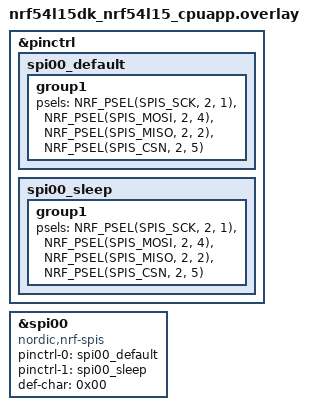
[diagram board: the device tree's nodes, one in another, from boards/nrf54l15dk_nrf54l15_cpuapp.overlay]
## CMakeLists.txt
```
# Copyright (c) 2023 ELMODIS Ltd.

cmake_minimum_required(VERSION 3.20.0)

find_package(Zephyr REQUIRED HINTS $ENV{ZEPHYR_BASE})
project(hello_world)

target_sources(app PRIVATE
    src/main.c
    src/ade9000.c
    src/ade9000Estimates.c
    src/ade9000Interface.c
    src/ble_gatt_service.c
    src/bas_gatt.c
    ${app_sources}
)

zephyr_library_include_directories(${ZEPHYR_BASE}/samples/bluetooth)
```

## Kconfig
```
# Copyright (c) 2023 ELMODIS Ltd.

mainmenu "Elmodis EnergyTag demo"

config ADC_MAX_NUMBER_OF_CHANNELS
	int "Maximum nubmer of ADC channels"
	range 0 255
	help
	  CONFIG_ADC_MAX_NUMBER_OF_CHANNELS must be defined in your prj.conf file

config ADC_CHANNEL_NAMES_USE
	bool "Use channel names assignment"
	default n
	help
	  Enables channel names feature for ADC stucture

config ESTIMATES_QUEUE_SIZE
	int "Size of estimates queue"
	default 1

source "Kconfig.zephyr"
```

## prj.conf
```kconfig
# nothing here
CONFIG_SPI=y
CONFIG_SPI_ASYNC=y
CONFIG_SPI_SLAVE=y
CONFIG_SPI_LOG_LEVEL_INF=y
CONFIG_DEBUG_OPTIMIZATIONS=y
```

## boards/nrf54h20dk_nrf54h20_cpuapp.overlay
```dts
&pinctrl {
	grtc_default_alt: grtc_default_alt {
		group1 {
			psels = <NRF_PSEL(GRTC_CLKOUT_32K, 0, 1)>,
				<NRF_PSEL(GRTC_CLKOUT_FAST, 1, 8)>;
		};
	};
};

&grtc {
	compatible = "nordic,nrf-grtc";
	pinctrl-0 = <&grtc_default_alt>;
	pinctrl-names = "default";
};
```

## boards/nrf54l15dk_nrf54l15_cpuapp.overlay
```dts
&pinctrl {
    spi00_default: spi00_default {
        group1 {
            psels = <NRF_PSEL(SPIS_SCK, 2, 1)>,  /* SCK Input */
                    <NRF_PSEL(SPIS_MOSI, 2, 4)>, /* MOSI Input */
                    <NRF_PSEL(SPIS_MISO, 2, 2)>, /* MISO Output */
                    <NRF_PSEL(SPIS_CSN, 2, 5)>;  /* CS Input - Must be here! */
        };
    };
    spi00_sleep: spi00_sleep {
        group1 {
            psels = <NRF_PSEL(SPIS_SCK, 2, 1)>,  /* SCK Input */
                    <NRF_PSEL(SPIS_MOSI, 2, 4)>, /* MOSI Input */
                    <NRF_PSEL(SPIS_MISO, 2, 2)>, /* MISO Output */
                    <NRF_PSEL(SPIS_CSN, 2, 5)>;  /* CS Input - Must be here! */
        };
    };
};

&spi00 {
    status = "okay";
    compatible = "nordic,nrf-spis";
    pinctrl-0 = <&spi00_default>;
    pinctrl-1 = <&spi00_sleep>;
    pinctrl-names = "default","sleep";
    def-char = <0x00>;
    /delete-property/ rx-delay-supported;
    /delete-property/ rx-delay;
};
```

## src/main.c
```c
#include <zephyr/device.h>
#include <zephyr/devicetree.h>
#include <zephyr/kernel.h>
#include <zephyr/types.h>
#include <zephyr/drivers/spi.h>

#define SPI_NODE DT_NODELABEL(spi00)
static const struct device *spi_dev = DEVICE_DT_GET(SPI_NODE);

struct spi_config spis_cfg = {
          .frequency = 0, /* Frequency is controlled entirely by the Master */
        .operation = SPI_WORD_SET(8) | SPI_OP_MODE_SLAVE,
};



int main(void)
{
	int err;
	int ret;
	int ret_val;
	uint8_t rx_buffer[32] = {
	                  0xab,0xcd,0xef,0xee,0xaa,0xff,0x12,0x89,
	                  0xab,0xcd,0xef,0xee,0xaa,0xff,0x12,0x89,
	                  0xab,0xcd,0xef,0xee,0xaa,0xff,0x12,0x89,
	                  0xab,0xcd,0xef,0xee,0xaa,0xff,0x12,0x89
	                        };
	uint8_t tx_buffer[32] = {
	                  0xab,0xcd,0xef,0xee,0xaa,0xff,0x12,0x89,
	                  0xab,0xcd,0xef,0xee,0xaa,0xff,0x12,0x89,
	                  0xab,0xcd,0xef,0xee,0xaa,0xff,0x12,0x89,
	                  0xab,0xcd,0xef,0xee,0xaa,0xff,0x12,0x89
	                        };


    if (!device_is_ready(spi_dev)) {
		printk("UART device not found!");
		return 0;
	}

	while (true) {
			printk("waiting for request\r\n");
		
    struct spi_buf tx_buf = { .buf = tx_buffer, .len = sizeof(tx_buffer) };
    struct spi_buf_set tx_bufs = { .buffers = &tx_buf, .count = 1 };

    struct spi_buf rx_buf = { .buf = rx_buffer, .len = sizeof(rx_buffer) };
    struct spi_buf_set rx_bufs = { .buffers = &rx_buf, .count = 1 };
  		ret = spi_transceive(spi_dev, &spis_cfg, &tx_bufs, &rx_bufs);
        printk("received %d bytes:", ret);
        for (int i = 0; i < ret && i < sizeof(rx_buffer); i++) {
                printk(" %02x", rx_buffer[i]);
        }
        printk("\n");

  		printk("spi work done\n");
				
	}

	/* return to idle thread */
	return 0;
}
```

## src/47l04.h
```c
/*
 * Copyright (c) 2023 ELMODIS Ltd.
 */

#define L04_ADDR           0x20
#define L04_SCL_PIN        27
#define L04_SDA_PIN        26

// 47L04-I/ST register addresses
#define L04_REG_INPUT      0x00
#define L04_REG_OUTPUT     0x01
#define L04_REG_CONFIG     0x03
```

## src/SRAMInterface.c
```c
/*
 * Copyright (c) 2023 ELMODIS Ltd.
 */

#include "SRAMInterface.h"
#include <zephyr/kernel.h>

// TODO: Get from config
//#define LOG_SRAMINTERFACE 1
#define SRAM_TX_BUFFER_SIZE 16
#define SRAM_RX_BUFFER_SIZE 16

#if defined(LOG_SRAMINTERFACE) && (LOG_SRAMINTERFACE == 1)
#include <zephyr/sys/printk.h>
#endif

//TODO: Get it from DeviceTree
#define SRAM_CS_PIN   29//0x1F // 31
#define SRAM_MOSI_PIN 17 // 32
//TODO: This pin is temporary and should be 15 (some DK/DTS problems?)
#define SRAM_MISO_PIN (32 + 11) // 15
#define SRAM_SCK_PIN  13 // default 22

static volatile uint8_t m_rx_buffer[16];
static volatile uint8_t m_tx_buffer[16];

static volatile bool spi_flag = true;

static void WaitForTransferEnd(bool resetFlag)
{
    while(!spi_flag);
    if (resetFlag) {
        spi_flag = false;
    }
}

static void spim_handler(const nrfx_spim_evt_t *p_event, void *p_context)
{
	if (p_event->type == NRFX_SPIM_EVENT_DONE) {
#if defined(LOG_SRAMINTERFACE) && (LOG_SRAMINTERFACE == 1)
        printk(" (IRQ)\n");
#endif
        spi_flag = true;
        memset((void*)m_tx_buffer , 0 , sizeof(m_tx_buffer));
	}
}

#warning change instance
static const nrfx_spim_t spi_inst = NRFX_SPIM_INSTANCE(2);

static bool SPIInit(void)
{
    nrfx_spim_config_t spi_config = NRFX_SPIM_DEFAULT_CONFIG(SRAM_SCK_PIN,
                                                             SRAM_MOSI_PIN,
                                                             SRAM_MISO_PIN,
                                                             SRAM_CS_PIN);

    return nrfx_spim_init(&spi_inst, &spi_config, spim_handler, NULL) == NRFX_SUCCESS ?
           true : false;
}

bool SRAMInit(void)
{
    /*if (!SRAMInterfaceInit()) {
        return false;
    }*/
    if (!SPIInit()) {
        return false;
    }
    return true;
}

bool SRAMWrite(uint32_t addr, uint8_t const * const data, size_t length)
{
    WaitForTransferEnd(true);
    addr &= 0x00FFFFFF;
    m_tx_buffer[0] = 0x02;
    m_tx_buffer[1] = (uint8_t)(addr >> 16);
    m_tx_buffer[2] = (uint8_t)(addr >> 8);
    m_tx_buffer[3] = (uint8_t)(addr >> 0);
    memcpy((uint8_t*)&m_tx_buffer[4], (uint8_t*)data, length);
    length += 4;
    nrfx_spim_xfer_desc_t spim_xfer_desc = NRFX_SPIM_XFER_TX(m_tx_buffer, 4 + length);
    nrfx_err_t err = nrfx_spim_xfer(&spi_inst, &spim_xfer_desc, 0);
    return err == NRFX_SUCCESS;
}

uint8_t * SRAMRead(uint32_t addr, size_t length)
{
    WaitForTransferEnd(true);
    addr &= 0x00FFFFFF;
    m_tx_buffer[0] = 0x03;
    m_tx_buffer[1] = (uint8_t)(addr >> 16);
    m_tx_buffer[2] = (uint8_t)(addr >> 8);
    m_tx_buffer[3] = (uint8_t)(addr >> 0);

    memset((uint8_t*)m_rx_buffer, 0, sizeof(m_rx_buffer));
    
    nrfx_spim_xfer_desc_t spim_xfer_desc = NRFX_SPIM_XFER_TRX(m_tx_buffer, 4 ,(uint8_t*)m_rx_buffer , length + 4);
    nrfx_err_t err = nrfx_spim_xfer(&spi_inst, &spim_xfer_desc, 0);
    WaitForTransferEnd(false);
    return err == NRFX_SUCCESS ? &m_rx_buffer[4] : NULL;
}

bool SRAMIDRead(uint8_t * id)
{
    WaitForTransferEnd(true);
    uint32_t addr = 0xFFFFFFFF;
    size_t length = 8;
    m_tx_buffer[0] = 0x9F;
    m_tx_buffer[1] = (uint8_t)(addr >> 16);
    m_tx_buffer[2] = (uint8_t)(addr >> 8);
    m_tx_buffer[3] = (uint8_t)(addr >> 0);

    memset((uint8_t*)m_rx_buffer, 0, sizeof(m_rx_buffer));
    
    nrfx_spim_xfer_desc_t spim_xfer_desc = NRFX_SPIM_XFER_TRX(m_tx_buffer, 4 ,(uint8_t*)m_rx_buffer , length + 4);
    nrfx_err_t err = nrfx_spim_xfer(&spi_inst, &spim_xfer_desc, 0);
    WaitForTransferEnd(false);
    id = (uint8_t*)m_rx_buffer;
    return err == NRFX_SUCCESS;
}

void SRAMReset(void)
{
    //0x66, 0x99
    WaitForTransferEnd(true);
    m_tx_buffer[0] = 0x66;
    
    size_t length = 1;
    nrfx_spim_xfer_desc_t spim_xfer_desc = NRFX_SPIM_XFER_TX(m_tx_buffer, length);
    (void)nrfx_spim_xfer(&spi_inst, &spim_xfer_desc, 0);
    WaitForTransferEnd(true);
    k_sleep(K_MSEC(10));
    m_tx_buffer[0] = 0x99;
    (void)nrfx_spim_xfer(&spi_inst, &spim_xfer_desc, 0);
    WaitForTransferEnd(false);
}
```

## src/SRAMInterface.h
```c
/*
 * Copyright (c) 2023 ELMODIS Ltd.
 */

#ifndef SRAMINTERFACE_H
#define SRAMINTERFACE_H

#include <nrfx_spim.h>
#include <stdlib.h>
#include <string.h>

bool SRAMInit(void);

bool SRAMWrite(uint32_t addr, uint8_t const * const data, size_t length);

uint8_t * SRAMRead(uint32_t addr, size_t length);

bool SRAMIDRead(uint8_t * id);

void SRAMReset(void);

#endif // SRAMINTERFACE_H
```

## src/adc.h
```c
#ifndef ADC_H
#define ADC_H

typedef struct {
    bool (*initialize)(void *);
    bool (*configure)(void *);
    bool (*start) (void *);
    bool (*stop) (void *);
    bool (*channel_read) (uint8_t chan, void *);
    bool (*all_channels_read) (void *);
#if IS_ENABLED(CONFIG_ADC_CHANNEL_NAMES_USE)
    const char *channel_name[CONFIG_ADC_MAX_NUMBER_OF_CHANNELS];
#endif
} adc_t;

#define ADC_INITIALIZE_STRUCT(        			 \
            init_func,                			 \
            config_func,              			 \
            start_func,               			 \
            stop_func,                			 \
            channel_read_func,				 \
	    all_channels_read_func)                	 \
        {                             			 \
            .initialize = init_func,  			 \
            .configure = config_func, 			 \
            .start = start_func,      			 \
	    .stop = stop_func,        			 \
	    .channel_read = channel_read_func, 		 \
	    .all_channels_read = all_channels_read_func  \
        }

#if IS_ENABLED(CONFIG_ADC_CHANNEL_NAMES_USE)
#define ADC_CHANNEL_NAME_ASSIGN(adc, channel, name) \
	adc.channel_name[channel] = name

#define ADC_CHANNEL_NAME_GET(adc, channel) \
	adc.channel_name[channel]
#endif

#endif // ADC_H
```

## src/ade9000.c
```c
/*
 * Copyright (c) 2023 ELMODIS Ltd.
 */

#include <zephyr/drivers/gpio.h>
#include <zephyr/kernel.h>
#if 1
#include <zephyr/sys/printk.h>
#endif

#include "ade9000_registers.h"
#include "ade9000Estimates.h"

//#define ADE9000_PM0_NODE   DT_ALIAS(ade9000pm0)
#define ADE9000_PM1_NODE   DT_ALIAS(ade9000pm1)
#define ADE9000_RESET_NODE DT_ALIAS(ade9000reset)
#define ADE9000_DRDY_NODE  DT_ALIAS(ade9000drdy)
#define ADE9000_IRQ0_NODE  DT_ALIAS(ade9000irq0)
#define ADE9000_IRQ1_NODE  DT_ALIAS(ade9000irq1)

// TODO: Move out and rework when error handling will be finished.
#define CHECK_RESULT_BOOL(expression) \
        if (!expression) return false;

//static const struct gpio_dt_spec pm0   = GPIO_DT_SPEC_GET(ADE9000_PM0_NODE, gpios);
static const struct gpio_dt_spec pm1   = GPIO_DT_SPEC_GET(ADE9000_PM1_NODE, gpios);
static const struct gpio_dt_spec reset = GPIO_DT_SPEC_GET(ADE9000_RESET_NODE, gpios);
static const struct gpio_dt_spec drdy  = GPIO_DT_SPEC_GET(ADE9000_DRDY_NODE, gpios);
static const struct gpio_dt_spec irq0  = GPIO_DT_SPEC_GET(ADE9000_IRQ0_NODE, gpios);
static const struct gpio_dt_spec irq1  = GPIO_DT_SPEC_GET(ADE9000_IRQ1_NODE, gpios);

typedef enum {
    PM_Reduced = 0,
    PM_Normal  = 1,
    PM_Low     = 2,
    PM_Sleep   = 3
} ade9000_power_mode_t;

#define TEST_REG 0x4FE
#define EXPECTED_TEST_RESULT 0x00FE

#define TEST_MES  0xCFE

static bool GPIOConfig(void)
{
    int ret;
    // TODO: Looks bad. Array of pins to be initialized/configured
    if (!device_is_ready(reset.port)) {
		return false;
	}
	ret = gpio_pin_configure_dt(&reset, GPIO_OUTPUT_INACTIVE);
	if (ret < 0) {
		return false;
	}
    gpio_pin_set_dt(&reset, 1);
    //TODO: Check those timings.
    k_msleep(100);

  /*if (!device_is_ready(pm0.port)) {
		return false;
	}
	ret = gpio_pin_configure_dt(&pm0, GPIO_OUTPUT_ACTIVE);
	if (ret < 0) {
		return false;
	}*/

    if (!device_is_ready(pm1.port)) {
		return false;
	}
	ret = gpio_pin_configure_dt(&pm1, GPIO_OUTPUT_ACTIVE);
	if (ret < 0) {
		return false;
	}

    if (!device_is_ready(drdy.port)) {
		return false;
	}
	ret = gpio_pin_configure_dt(&drdy, GPIO_INPUT);
	if (ret < 0) {
		return false;
	}

    if (!device_is_ready(irq0.port)) {
		return false;
	}
	ret = gpio_pin_configure_dt(&irq0, GPIO_INPUT);
	if (ret < 0) {
		return false;
	}

    if (!device_is_ready(irq1.port)) {
		return false;
	}
	ret = gpio_pin_configure_dt(&irq1, GPIO_INPUT);
	if (ret < 0) {
		return false;
	}

    gpio_pin_set_dt(&irq0, 1);
    gpio_pin_set_dt(&irq1, 1);

    return true;
}

static bool PowerModeSet(ade9000_power_mode_t mode)
{
    switch(mode) {
        case PM_Normal:
            //gpio_pin_set_dt(&pm0, 0);
            gpio_pin_set_dt(&pm1, 0);
            break;
        default:
            // Other modes not supported at the moment.
            return false;
  }

  return true;
}
static void StoreCoeffs(SEleFlashDataCal *fd)
{
	int32_t default_coeff = 0;
	if (fd != NULL) {
	// TODO: Currently not supported
	while(1);
	}
	//default_coeff = 14528733;
	default_coeff = 383;
	ADE9000InterfaceRegWriteAndCheck(R_APHCAL0, default_coeff, 4);
	ADE9000InterfaceRegWriteAndCheck(R_BPHCAL0, default_coeff, 4);
	ADE9000InterfaceRegWriteAndCheck(R_CPHCAL0, default_coeff, 4);

	default_coeff = 0;
	ADE9000InterfaceRegWriteAndCheck(R_AIGAIN, -95119123, 4);
	ADE9000InterfaceRegWriteAndCheck(R_BIGAIN, -94938644, 4);
	ADE9000InterfaceRegWriteAndCheck(R_CIGAIN, -95003782, 4);

	default_coeff = 0;
	ADE9000InterfaceRegWriteAndCheck(R_AVGAIN, -115926529, 4);
	ADE9000InterfaceRegWriteAndCheck(R_BVGAIN, -115971651, 4);
	ADE9000InterfaceRegWriteAndCheck(R_CVGAIN, -115894056, 4);

	default_coeff = 0;
	ADE9000InterfaceRegWriteAndCheck(R_AIRMSOS, default_coeff, 4);
	ADE9000InterfaceRegWriteAndCheck(R_BIRMSOS, default_coeff, 4);
	ADE9000InterfaceRegWriteAndCheck(R_CIRMSOS, default_coeff, 4);

	default_coeff = 0;
	ADE9000InterfaceRegWriteAndCheck(R_AVRMSOS, default_coeff, 4);
	ADE9000InterfaceRegWriteAndCheck(R_BVRMSOS, default_coeff, 4);
	ADE9000InterfaceRegWriteAndCheck(R_CVRMSOS, default_coeff, 4);

	default_coeff = 0;
	ADE9000InterfaceRegWriteAndCheck(R_AWATTOS, default_coeff, 4);
	ADE9000InterfaceRegWriteAndCheck(R_BWATTOS, default_coeff, 4);
	ADE9000InterfaceRegWriteAndCheck(R_CWATTOS, default_coeff, 4);

	default_coeff = 0;
	ADE9000InterfaceRegWriteAndCheck(R_AVAROS, default_coeff, 4);
	ADE9000InterfaceRegWriteAndCheck(R_BVAROS, default_coeff, 4);
	ADE9000InterfaceRegWriteAndCheck(R_CVAROS, default_coeff, 4);

	default_coeff = 0;
	ADE9000InterfaceRegWriteAndCheck(R_APGAIN, 45687846, 4);
	ADE9000InterfaceRegWriteAndCheck(R_BPGAIN, 45903740, 4);
	ADE9000InterfaceRegWriteAndCheck(R_CPGAIN, 45847370, 4);
}

void EnergyAccConfigure(void)
{
    //aktywujemy i konfigurujemy akumulator energii
    //reg.S_EP_CFG.RD_RST_EN = 1;
    ade9000_reg32_t reg;
    uint32_t no_load_thr = 2;
    reg.v = no_load_thr * 64;
    ADE9000InterfaceRegWrite(R_ACT_NL_LVL, reg.v, sizeof(reg.S_ACT_NL_LVL));
    ADE9000InterfaceRegWrite(R_REACT_NL_LVL, reg.v, sizeof(reg.S_REACT_NL_LVL));
    ADE9000InterfaceRegWrite(R_APP_NL_LVL, reg.v, sizeof(reg.S_APP_NL_LVL));

    reg.v = 0;
    reg.S_EP_CFG.EGY_PWR_EN = 1;//Set this bit to enable the energy and power accumulator
    reg.S_EP_CFG.RD_RST_EN = 1;//Every read causes reset energy accumulator
    ADE9000InterfaceRegWrite(R_EP_CFG, reg.v, sizeof(reg.S_EP_CFG));

    reg.v = 8000;//Energy accumulation update time configuration.
    ADE9000InterfaceRegWrite(R_EGY_TIME, reg.v, sizeof(reg.S_EGY_TIME));

    reg.v = 0;
    reg.S_ACCMODE.WATTACC = 2;//Positive Accumuation Mode.
    reg.S_ACCMODE.VARACC = 2;//Positive Accumuation Mode.
    ADE9000InterfaceRegWrite(R_ACCMODE, reg.v, sizeof(reg.S_ACCMODE));
}

bool ADE9000Init(void * params)
{
	(void)params;
	if (!GPIOConfig()) {
	return false;
	}
	if (!PowerModeSet(PM_Normal)) {
	return false;
	}
	if (!ADE9000InterfaceInit()) {
	return false;
	}
	//TODO: Check those timings.
	k_msleep(10);
	gpio_pin_set_dt(&reset, 0);
	//TODO: Check those timings.
	k_msleep(100);

	return true;
}

bool ADE9000MeasParamsSet(void * params)
{
    (void)params;
    uint8_t i_gain = 1;
    uint8_t v_gain = 1;
    uint16_t u_g = v_gain - 1, i_g = i_gain - 1;
    ade9000_reg32_t reg;

    reg.v = 0;
    reg.S_PGA_GAIN.VA_GAIN = u_g;
    reg.S_PGA_GAIN.VB_GAIN = u_g;
    reg.S_PGA_GAIN.VC_GAIN = u_g;
    reg.S_PGA_GAIN.IA_GAIN = i_g;
    reg.S_PGA_GAIN.IB_GAIN = i_g;
    reg.S_PGA_GAIN.IC_GAIN = i_g;
    reg.S_PGA_GAIN.IN_GAIN = i_g;


    StoreCoeffs(NULL);
    EnergyAccConfigure();
    ADE9000InterfaceRegWriteAndCheck(R_PGA_GAIN, reg.v, 2);

    reg.v = 0;
    reg.S_ACCMODE.SELFSREQ = 1;
    ADE9000InterfaceRegWriteAndCheck(R_ACCMODE, reg.v,2);

    ADE9000InterfaceRegWriteAndCheck(R_DICOEFF, 0xFFFFE000, 4);
    ADE9000InterfaceRegRead(R_CONFIG0, &reg.v, sizeof(reg.S_CONFIG0));
    reg.S_CONFIG0.INTEN = 1;
    CHECK_RESULT_BOOL(ADE9000InterfaceRegWriteAndCheck(R_CONFIG0, reg.v, sizeof(reg.S_CONFIG0)));

    return true;
}


bool ADE9000ConversionStart(void * params)
{
  (void)params;
  ade9000_reg32_t reg, r_reg;
  //ADCData.MeasInProgress = 1;
  reg.v = 0;
  CHECK_RESULT_BOOL(ADE9000InterfaceRegWriteAndCheck(R_WFB_PG_IRQEN, 0x8080, 2));
  //konfiguracja przebiegow:
  CHECK_RESULT_BOOL(ADE9000InterfaceRegWriteAndCheck(R_WFB_CFG, reg.v,sizeof(reg.S_WFB_CFG)));
  reg.S_WFB_CFG.WF_MODE = 3;
  reg.S_WFB_CFG.WF_CAP_SEL = 1;
  reg.S_WFB_CFG.WF_CAP_EN = 1;
  reg.S_WFB_CFG.WF_SRC = 3;
  CHECK_RESULT_BOOL(ADE9000InterfaceRegWriteAndCheck(R_WFB_CFG, reg.v, sizeof(reg.S_WFB_CFG)));
  ADE9000InterfaceRegRead(R_WFB_CFG, &r_reg.v,sizeof(r_reg.S_WFB_CFG));
  if (r_reg.v != reg.v) return false;

  ADE9000InterfaceRegRead(R_CONFIG1, &reg.v, sizeof(reg.S_CONFIG1));
  reg.S_CONFIG1.BURST_EN = 1;
  reg.S_CONFIG1.CF4_CFG = 0x2;
  CHECK_RESULT_BOOL(ADE9000InterfaceRegWriteAndCheck(R_CONFIG1, reg.v, sizeof(reg.S_CONFIG1)));

  reg.v = 0;
  reg.S_EVENT_MASK.DREADY = 1;
  CHECK_RESULT_BOOL(ADE9000InterfaceRegWriteAndCheck(R_EVENT_MASK, reg.v, sizeof(reg.S_EVENT_MASK)));

  ADE9000InterfaceRegRead(R_RUN, &reg.v, sizeof(reg.S_RUN));

  if (!reg.S_RUN.Start) {
    reg.S_RUN.Start = 1;
    CHECK_RESULT_BOOL(ADE9000InterfaceRegWriteAndCheck(R_RUN,reg.v, sizeof(reg.S_RUN)));
  }

  return true;
}

void ADE9000StreamRead(void)
{
    //ADE9000InterfaceRegRead(R_AV_PCF_1 , (uint8_t*)m_rx_buffer, 28);
    k_sleep(K_SECONDS(1));
}
```

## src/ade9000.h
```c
/*
 * Copyright (c) 2023 ELMODIS Ltd.
 */

#ifndef ADE9000_H
#define ADE9000_H

#include <stdbool.h>

bool ADE9000Init(void * params);

bool ADE9000MeasParamsSet(void * params);

bool ADE9000ConversionStart(void * params);

void ADE9000StreamRead(void);

#endif // ADE9000_H
```

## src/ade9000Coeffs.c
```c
/*
 * Copyright (c) 2023 ELMODIS Ltd.
 */
```

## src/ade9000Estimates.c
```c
/*
 * Copyright (c) 2023 ELMODIS Ltd.
 */

#include <zephyr/kernel.h>
#include <math.h>

#include "ade9000Estimates.h"
#include "ade9000_registers.h"


// TODO: Get from config
#define LOG_ADE9000ESTIMATES 0

#if defined(LOG_ADE9000ESTIMATES) && (LOG_ADE9000ESTIMATES== 1)
#include <zephyr/sys/printk.h>
#endif

typedef struct estimates_seq_t{
  enum Eade9000_register Addr;
  int32_t DstOffs;
  uint8_t Size;
} estimates_seq_t;

static const estimates_seq_t EstimatesReadSequenceTable[] = {
    {R_AIRMS, offsetof(ade_est_data_t, IA), 4 },
    {R_AVRMS, offsetof(ade_est_data_t, VA), 4 },
    {R_BIRMS, offsetof(ade_est_data_t, IB), 4 },
    {R_BVRMS, offsetof(ade_est_data_t, VB), 4 },
    {R_CIRMS, offsetof(ade_est_data_t, IC), 4 },
    {R_CVRMS, offsetof(ade_est_data_t, VC), 4 },

    {R_AWATT, offsetof(ade_est_data_t, AWATT), 4 },
    {R_BWATT, offsetof(ade_est_data_t, BWATT), 4 },
    {R_CWATT, offsetof(ade_est_data_t, CWATT), 4 },

    {R_AVAR, offsetof(ade_est_data_t, AVAR), 4 },
    {R_BVAR, offsetof(ade_est_data_t, BVAR), 4 },
    {R_CVAR, offsetof(ade_est_data_t, CVAR), 4 },

    {R_AVA, offsetof(ade_est_data_t, AVA), 4 },
    {R_BVA, offsetof(ade_est_data_t, BVA), 4 },
    {R_CVA, offsetof(ade_est_data_t, CVA), 4 },

    {R_AWATTHR_HI, offsetof(ade_est_data_t, AWATTHR), 4 },
    {R_BWATTHR_HI, offsetof(ade_est_data_t, BWATTHR), 4 },
    {R_CWATTHR_HI, offsetof(ade_est_data_t, CWATTHR), 4 },

    {R_AVARHR_HI, offsetof(ade_est_data_t, AVARHR), 4 },
    {R_BVARHR_HI, offsetof(ade_est_data_t, BVARHR), 4 },
    {R_CVARHR_HI, offsetof(ade_est_data_t, CVARHR), 4 },

    {R_ANGL_VA_IA, offsetof(ade_est_data_t, Angle0), 2 },
    {R_ANGL_VB_IB, offsetof(ade_est_data_t, Angle1), 2 },
    {R_ANGL_VC_IC, offsetof(ade_est_data_t, Angle2), 2 },
};

static void AdditionalEstimatesCalculate(ade_est_data_t * estimates)
{
	static int32_t ea_last[3];
	static int32_t er_last[3];

	// TODO - remove as it is for 50Hz system only.
	estimates->Angle0 = (int32_t)(0.017578125 * (double)estimates->Angle0);
	estimates->Angle1 = (int32_t)(0.017578125 * (double)estimates->Angle1);
	estimates->Angle2 = (int32_t)(0.017578125 * (double)estimates->Angle2);

	estimates->Imean = (estimates->IA + estimates->IB + estimates->IC) / 3;
	estimates->Umean = (estimates->VA + estimates->VB + estimates->VC) / 3;

	ea_last[0] = (estimates->AWATTHR > 0) ? (ea_last[0] + estimates->AWATTHR) : (ea_last[0]);
	ea_last[1] = (estimates->BWATTHR > 0) ? (ea_last[1] + estimates->BWATTHR) : (ea_last[1]);
	ea_last[2] = (estimates->CWATTHR > 0) ? (ea_last[2] + estimates->CWATTHR) : (ea_last[2]);
	estimates->AWATTHR = ea_last[0];
	estimates->BWATTHR = ea_last[1];
	estimates->CWATTHR = ea_last[2];
	estimates->WATTHR = estimates->AWATTHR + estimates->BWATTHR + estimates->CWATTHR;

	er_last[0] = (estimates->AVARHR > 0) ? (er_last[0] + estimates->AVARHR) : (er_last[0]);
	er_last[1] = (estimates->BVARHR > 0) ? (er_last[1] + estimates->BVARHR) : (er_last[1]);
	er_last[2] = (estimates->CVARHR > 0) ? (er_last[2] + estimates->CVARHR) : (er_last[2]);
	estimates->AVARHR = er_last[0];
	estimates->BVARHR = er_last[1];
	estimates->CVARHR = er_last[2];
	estimates->WARTHR = estimates->AVARHR + estimates->BVARHR + estimates->CVARHR;

	estimates->P = estimates->AWATT + estimates->BWATT + estimates->CWATT;
	estimates->Q = estimates->AVAR + estimates->BVAR + estimates->CVAR;
	estimates->S = estimates->AVA + estimates->BVA + estimates->CVA;

	estimates->VAB = (int32_t)(((estimates->VA + estimates->VB) / 2) * sqrt(3));
	estimates->VBC = (int32_t)(((estimates->VB + estimates->VC) / 2) * sqrt(3));
	estimates->VCA = (int32_t)(((estimates->VC + estimates->VA) / 2) * sqrt(3));
}

bool ADE9000EstimatesAllEstimates1sRead(void *p_est)
{
	//__ASSERT(p_est);
	uint32_t * read_data = (uint32_t *)p_est;
	for(uint32_t i = 0; i < ARRAY_SIZE(EstimatesReadSequenceTable); i ++) {
		if (!ADE9000InterfaceRegRead(EstimatesReadSequenceTable[i].Addr,
            				     &read_data[i],
            				     EstimatesReadSequenceTable[i].Size)) {
			return false;
		}
		while(!ADE9000InterfaceTransferDone()) {
			//TODO: use semaphores?
			k_usleep(10);
		}
	}
	AdditionalEstimatesCalculate((ade_est_data_t *)p_est);
	return true;
}

bool ADE9000EstimatesEstimate1sRead(uint8_t idx, void *p_est)
{
    if (idx >= ARRAY_SIZE(EstimatesReadSequenceTable)) {
      return false;
    }

    ADE9000InterfaceRegRead(EstimatesReadSequenceTable[idx].Addr,
            (uint32_t *)p_est,
            EstimatesReadSequenceTable[idx].Size);
#if defined(LOG_ADE9000ESTIMATES) && (LOG_ADE9000ESTIMATES== 1)
    while(!ADE9000InterfaceTransferDone());
    printk("Estimate(%s) = %d\n", EstimStringArray[idx], (uint32_t)*p_est);
#endif
    return true;
}
```

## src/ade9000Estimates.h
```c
/*
 * Copyright (c) 2023 ELMODIS Ltd.
 */

#ifndef ADE9000ESTIMATES_H
#define ADE9000ESTIMATES_H

#include "ade9000Interface.h"

typedef struct {

} ade9000_read_data_t;

typedef struct ade_est_data_t {
   int32_t IA;
   int32_t VA;
   int32_t IB;
   int32_t VB;
   int32_t IC;
   int32_t VC;

   int32_t AWATT;
   int32_t BWATT;
   int32_t CWATT;

   int32_t AVAR;
   int32_t BVAR;
   int32_t CVAR;

   int32_t AVA;
   int32_t BVA;
   int32_t CVA;

   int32_t AWATTHR;
   int32_t BWATTHR;
   int32_t CWATTHR;

   int32_t AVARHR;
   int32_t BVARHR;
   int32_t CVARHR;

   int32_t Angle0;
   int32_t Angle1;
   int32_t Angle2;

   int32_t VAB;
   int32_t VBC;
   int32_t VCA;

   int32_t Imean;
   int32_t Umean;

   int32_t P;
   int32_t Q;
   int32_t S;

   uint32_t WATTHR;
   uint32_t WARTHR;

   int32_t ModuleTemperature;
   uint32_t PMS;
   uint32_t FrameCounter;
   uint64_t Timestamp;
   uint32_t Checksum;
} ade_est_data_t;

bool ADE9000EstimatesAllEstimates1sRead(void *p_est);

bool ADE9000EstimatesEstimate1sRead(uint8_t idx, void *p_est);

bool ADE9000EstimatesEstimate1sStart(void);

#endif // ADE9000ESTIMATES_H
```

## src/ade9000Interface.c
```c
/*
 * Copyright (c) 2023 ELMODIS Ltd.
 */

#include "ade9000Interface.h"

// TODO: Get from config
//#define LOG_ADE9000INTERFACE 1

#if defined(LOG_ADE9000INTERFACE) && (LOG_ADE9000INTERFACE == 1)
#include <zephyr/sys/printk.h>
#endif

//TODO: Get it from DeviceTree
#define ADE9000_CS_PIN   0x1F // 31
#define ADE9000_MOSI_PIN 0X20 // 32
#define ADE9000_MISO_PIN 0x18 // 24
#define ADE9000_SCK_PIN  22 // default 22

static volatile uint8_t m_rx_buffer[6];
static volatile uint8_t m_tx_buffer[4];

static volatile bool spi_flag = true;

static void WaitForTransferEnd(bool resetFlag)
{
    while(!spi_flag);
    if (resetFlag) {
        spi_flag = false;
    }
}

static void spim_handler(const nrfx_spim_evt_t *p_event, void *p_context)
{
	if (p_event->type == NRFX_SPIM_EVENT_DONE) {
#if defined(LOG_ADE9000INTERFACE) && (LOG_ADE9000INTERFACE == 1)
        printk(" (IRQ)\n");
#endif
        spi_flag = true;
        memset((void*)m_tx_buffer , 0 , sizeof(m_tx_buffer));
	}
}

bool ADE9000InterfaceTransferDone(void)
{
    return spi_flag;
}

static const nrfx_spim_t spi_inst = NRFX_SPIM_INSTANCE(1);

static bool SPIInit(void)
{
    nrfx_spim_config_t spi_config = NRFX_SPIM_DEFAULT_CONFIG(ADE9000_SCK_PIN,
                                                             ADE9000_MOSI_PIN,
                                                             ADE9000_MISO_PIN,
                                                             ADE9000_CS_PIN);

    return nrfx_spim_init(&spi_inst, &spi_config, spim_handler, NULL) == NRFX_SUCCESS ?
           true : false;
}

bool ADE9000InterfaceRegWrite(uint16_t addr , uint32_t data, unsigned char length) {
#if defined(LOG_ADE9000INTERFACE) && (LOG_ADE9000INTERFACE == 1)
    printk("Write\n  ");
#endif
    if (((length != 2) && (length != 4)) || (addr > 0xFFF0)) {
        while(1);
    }
    if (length == 2) {
        uint16_t *p16 = (uint16_t*)&data;
        *p16 = __REVSH(*p16);
    }
    else if (length == 4) {
        uint32_t *p32 = (uint32_t*)&data;
        *p32 = __REV(*p32);
    }
    WaitForTransferEnd(true);
    m_tx_buffer[0] = (uint8_t)(addr >> 8);
    m_tx_buffer[1] = (uint8_t)addr;
    memcpy((uint8_t*)&m_tx_buffer[2], &data, length);
#if defined(LOG_ADE9000INTERFACE) && (LOG_ADE9000INTERFACE == 1)
    printk("W:");
    for (uint32_t i = 0; i < (2 + length); i++) {
        printk(" %02X", m_tx_buffer[i]);
    }
    printk("\n");
#endif
    nrfx_spim_xfer_desc_t spim_xfer_desc = NRFX_SPIM_XFER_TX(m_tx_buffer, 2 + length);
    nrfx_err_t err = nrfx_spim_xfer(&spi_inst, &spim_xfer_desc, 0);
#if defined(LOG_ADE9000INTERFACE) && (LOG_ADE9000INTERFACE == 1)
    if (err != NRFX_SUCCESS) {
        printk("Err code: %x\n", err);
    }
#endif
    return err == NRFX_SUCCESS;
}

bool ADE9000InterfaceRegRead(uint16_t addr ,uint32_t * rcv_data, unsigned char rcv_lenght)
{
#if defined(LOG_ADE9000INTERFACE) && (LOG_ADE9000INTERFACE == 1)
    printk("Read\n  ");
#endif
    WaitForTransferEnd(true);
    addr |= 0x0008;
    m_tx_buffer[0] = (uint8_t)(addr >> 8);
    m_tx_buffer[1] = (uint8_t)addr;
#if defined(LOG_ADE9000INTERFACE) && (LOG_ADE9000INTERFACE == 1)
    printk("R:");
    for (uint32_t i = 0; i < 2; i++)
    {
        printk(" %02X", m_tx_buffer[i]);
    }
    printk("\n");
#endif
    //memcpy(tmp_send+2 , data , sizeof(uint8_t) * lenght);
    *rcv_data = 0;
    memset((uint8_t*)m_rx_buffer, 0, sizeof(m_rx_buffer));
    nrfx_spim_xfer_desc_t spim_xfer_desc = NRFX_SPIM_XFER_TRX(m_tx_buffer, 2 ,(uint8_t*)m_rx_buffer , rcv_lenght + 2);
    nrfx_err_t err = nrfx_spim_xfer(&spi_inst, &spim_xfer_desc, 0);
    WaitForTransferEnd(false);
    memcpy(rcv_data, (uint32_t*)&m_rx_buffer[2], sizeof(uint32_t));
    if(rcv_lenght == 4) {
        uint32_t * p32 = (uint32_t*)rcv_data;
        *p32 = __REV(*p32);
    }
    else if(rcv_lenght == 2) {
        uint16_t * p16 = (uint16_t*)rcv_data;
        *p16 = __REVSH(*p16);
    }
#if defined(LOG_ADE9000INTERFACE) && (LOG_ADE9000INTERFACE == 1)
    if (err == NRFX_SUCCESS)
    {
        printk("  <->");
        for (uint32_t i = 2; i < rcv_lenght + 2; i++)
        {
            printk(" %02X", m_rx_buffer[i]);
        }
        printk("\n");
    }
    else
    {
        printk("Err code: %x\n", err);
    }
#endif
    return err == NRFX_SUCCESS;
}

bool ADE9000InterfaceRegWriteAndCheck(uint16_t addr , uint32_t data , unsigned char length)
{
    uint32_t rcv_data;
#if defined(LOG_ADE9000INTERFACE) && (LOG_ADE9000INTERFACE == 1)
    printk("WriteAndCheck\n  ");
#endif
    ADE9000InterfaceRegWrite(addr, data, length);
#if defined(LOG_ADE9000INTERFACE) && (LOG_ADE9000INTERFACE == 1)
    printk("  Verify:\n  ");
#endif
    ADE9000InterfaceRegRead(addr, &rcv_data, length);
    return data == rcv_data;
}

bool ADE9000InterfaceInit(void)
{
    if (!SPIInit()) {
        return false;
    }
    return true;
}
```

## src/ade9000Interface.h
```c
/*
 * Copyright (c) 2023 ELMODIS Ltd.
 */

#ifndef ADE9000INTERFACE_H
#define ADE9000INTERFACE_H

#include <nrfx_spim.h>
#include <stdlib.h>
#include <string.h>

bool ADE9000InterfaceInit(void);

bool ADE9000InterfaceRegWrite(uint16_t addr , uint32_t data, unsigned char length);

bool ADE9000InterfaceRegRead(uint16_t addr , uint32_t *rcv_data, unsigned char rcv_lenght);

bool ADE9000InterfaceRegWriteAndCheck(uint16_t addr , uint32_t data , unsigned char length);

bool ADE9000InterfaceTransferDone(void);

#endif // ADE9000INTERFACE_H
```
